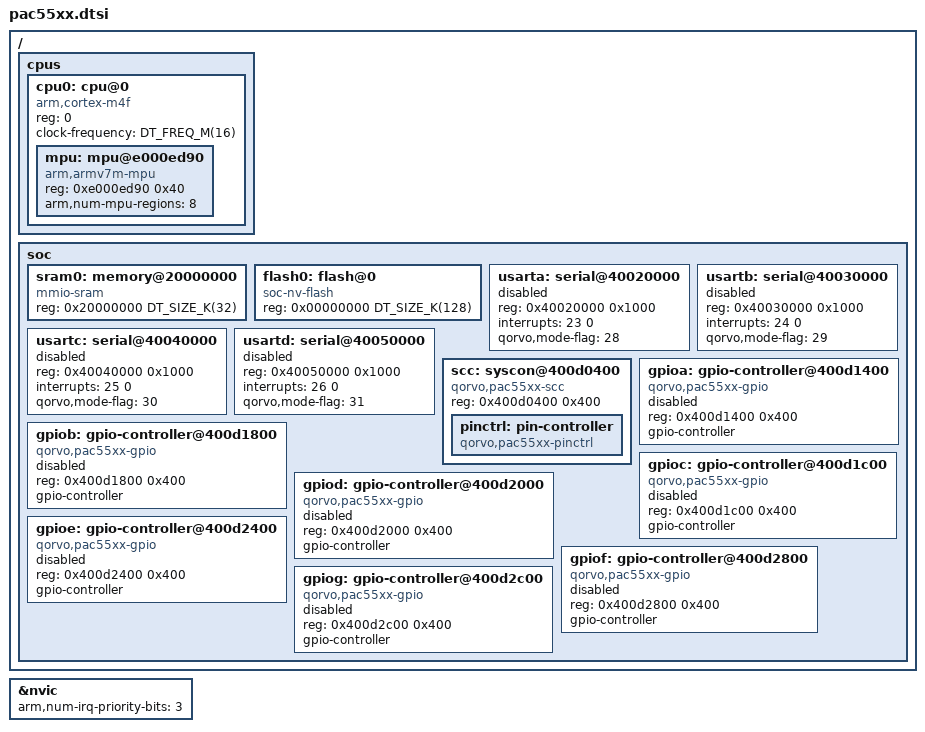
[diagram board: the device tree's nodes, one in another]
/*
 * Copyright (c) 2023, Teslabs Engineering S.L.
 * SPDX-License-Identifier: Apache-2.0
 */

#include <arm/armv7-m.dtsi>
#include <mem.h>
#include <freq.h>

/ {
	cpus {
		#address-cells = <1>;
		#size-cells = <0>;

		cpu0: cpu@0 {
			compatible = "arm,cortex-m4f";
			reg = <0>;
			#address-cells = <1>;
			#size-cells = <1>;
			clock-frequency = <DT_FREQ_M(16)>;

			mpu: mpu@e000ed90 {
				compatible = "arm,armv7m-mpu";
				reg = <0xe000ed90 0x40>;
				arm,num-mpu-regions = <8>;
			};
		};
	};

	soc {
		sram0: memory@20000000 {
			compatible = "mmio-sram";
			reg = <0x20000000 DT_SIZE_K(32)>;
		};

		flash0: flash@0 {
			compatible = "soc-nv-flash";
			reg = <0x00000000 DT_SIZE_K(128)>;
		};

		usarta: serial@40020000 {
			/* for UART mode: compatible = "qorvo,pac55xx-usart" */
			reg = <0x40020000 0x1000>;
			interrupts = <23 0>;
			status = "disabled";
			qorvo,mode-flag = <28>;
		};

		usartb: serial@40030000 {
			/* for UART mode: compatible = "qorvo,pac55xx-usart" */
			reg = <0x40030000 0x1000>;
			interrupts = <24 0>;
			status = "disabled";
			qorvo,mode-flag = <29>;
		};

		usartc: serial@40040000 {
			/* for UART mode: compatible = "qorvo,pac55xx-usart" */
			reg = <0x40040000 0x1000>;
			interrupts = <25 0>;
			status = "disabled";
			qorvo,mode-flag = <30>;
		};

		usartd: serial@40050000 {
			/* for UART mode: compatible = "qorvo,pac55xx-usart" */
			reg = <0x40050000 0x1000>;
			interrupts = <26 0>;
			status = "disabled";
			qorvo,mode-flag = <31>;
		};

		scc: syscon@400d0400 {
			compatible = "qorvo,pac55xx-scc", "simple-mfd", "syscon";
			reg = <0x400d0400 0x400>;

			pinctrl: pin-controller {
				compatible = "qorvo,pac55xx-pinctrl";
			};
		};

		gpioa: gpio-controller@400d1400 {
			compatible = "qorvo,pac55xx-gpio";
			reg = <0x400d1400 0x400>;
			status = "disabled";
			gpio-controller;
			#gpio-cells = <2>;
		};

		gpiob: gpio-controller@400d1800 {
			compatible = "qorvo,pac55xx-gpio";
			reg = <0x400d1800 0x400>;
			status = "disabled";
			gpio-controller;
			#gpio-cells = <2>;
		};

		gpioc: gpio-controller@400d1c00 {
			compatible = "qorvo,pac55xx-gpio";
			reg = <0x400d1c00 0x400>;
			status = "disabled";
			gpio-controller;
			#gpio-cells = <2>;
		};

		gpiod: gpio-controller@400d2000 {
			compatible = "qorvo,pac55xx-gpio";
			reg = <0x400d2000 0x400>;
			status = "disabled";
			gpio-controller;
			#gpio-cells = <2>;
		};

		gpioe: gpio-controller@400d2400 {
			compatible = "qorvo,pac55xx-gpio";
			reg = <0x400d2400 0x400>;
			status = "disabled";
			gpio-controller;
			#gpio-cells = <2>;
		};

		gpiof: gpio-controller@400d2800 {
			compatible = "qorvo,pac55xx-gpio";
			reg = <0x400d2800 0x400>;
			status = "disabled";
			gpio-controller;
			#gpio-cells = <2>;
		};

		gpiog: gpio-controller@400d2c00 {
			compatible = "qorvo,pac55xx-gpio";
			reg = <0x400d2c00 0x400>;
			status = "disabled";
			gpio-controller;
			#gpio-cells = <2>;
		};
	};
};

&nvic {
	arm,num-irq-priority-bits = <3>;
};
